# STM32L0x0 register map
File version: 1.1
CPU: CM0+ r0p0, little endian, MPU, no FPU, 4 interrupt priority bits
Registers are 32-bit, read-write, reset 0x0 unless marked. A register's access mark holds for its fields unless they carry their own. Offsets are from the block's base; [hi:lo] are bit positions; {n}, {i} and the like mark numbered series.

## Flash
Base 0x40022000
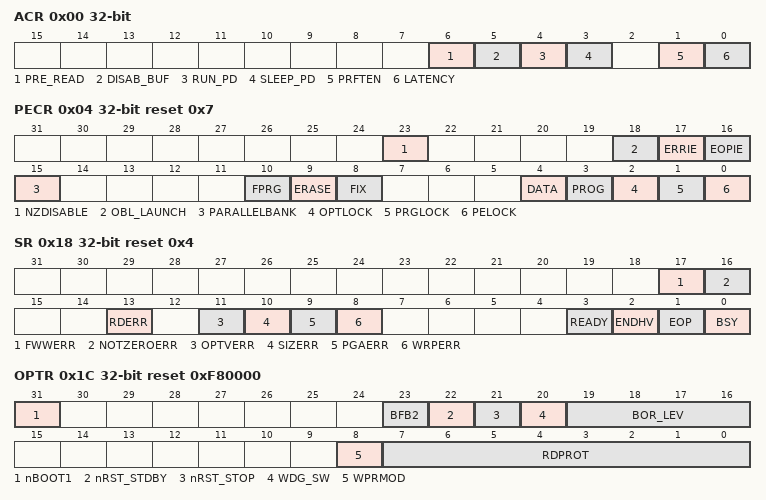
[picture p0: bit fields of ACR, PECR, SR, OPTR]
0x00 ACR — Access control register
  [6] PRE_READ — Pre-read data address
  [5] DISAB_BUF — Disable Buffer
  [4] RUN_PD — Flash mode during Run
  [3] SLEEP_PD — Flash mode during Sleep
  [1] PRFTEN — Prefetch enable
  [0] LATENCY
0x04 PECR reset 0x7 — Program/erase control register
  [23] NZDISABLE — Non-Zero check notification disable
  [18] OBL_LAUNCH — Launch the option byte loading
  [17] ERRIE — Error interrupt enable
  [16] EOPIE — End of programming interrupt enable
  [15] PARALLELBANK — Parallel bank mode
  [10] FPRG — Half Page/Double Word programming mode
  [9] ERASE — Page or Double Word erase mode
  [8] FIX — Fixed time data write for Byte, Half Word and Word programming
  [4] DATA — Data EEPROM selection
  [3] PROG — Program memory selection
  [2] OPTLOCK — Option bytes block lock
  [1] PRGLOCK — Program memory lock
  [0] PELOCK — FLASH_PECR and data EEPROM lock
0x08 PDKEYR wo — Power down key register
  [31:0] PDKEYR — RUN_PD in FLASH_ACR key
0x0C PEKEYR wo — Program/erase key register
  [31:0] PEKEYR — FLASH_PEC and data EEPROM key
0x10 PRGKEYR wo — Program memory key register
  [31:0] PRGKEYR — Program memory key
0x14 OPTKEYR wo — Option byte key register
  [31:0] OPTKEYR — Option byte key
0x18 SR access per field reset 0x4 — Status register
  [17] FWWERR rw
  [16] NOTZEROERR rw
  [13] RDERR rw
  [11] OPTVERR rw — Option validity error
  [10] SIZERR rw — Size error
  [9] PGAERR rw — Programming alignment error
  [8] WRPERR rw — Write protected error
  [3] READY ro — Flash memory module ready after low power mode
  [2] ENDHV ro — End of high voltage
  [1] EOP ro — End of operation
  [0] BSY ro — Write/erase operations in progress
0x1C OPTR ro reset 0xF80000 — Option byte register
  [31] nBOOT1
  [23] BFB2
  [22] nRST_STDBY
  [21] nRST_STOP
  [20] WDG_SW
  [19:16] BOR_LEV
  [8] WPRMOD
  [7:0] RDPROT — Read protection
0x20 WRPROT1 ro — Write protection register
  [31:0] WRPROT1 — Write protection
0x80 WRPROT2 ro — Write protection register
  [15:0] WRPROT2 — Write protection

## EXTI — External interrupt/event controller
Base 0x40010400
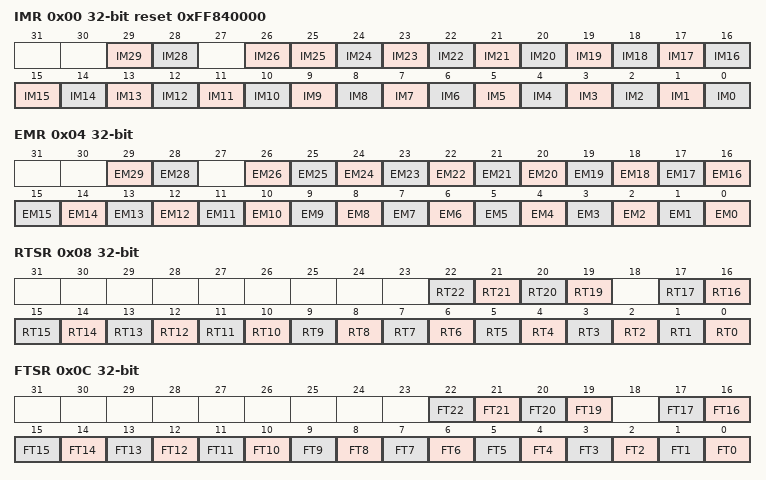
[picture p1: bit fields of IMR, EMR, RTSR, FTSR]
0x00 IMR reset 0xFF840000 — Interrupt mask register (EXTI_IMR)
  [29] IM29 — Interrupt Mask on line 27
  [28] IM28 — Interrupt Mask on line 27
  [26] IM26 — Interrupt Mask on line 27
  [n] IM{n} (n=0..25) — Interrupt Mask on line {n}
0x04 EMR — Event mask register (EXTI_EMR)
  [29] EM29 — Event Mask on line 29
  [28] EM28 — Event Mask on line 28
  [n] EM{n} (n=0..26) — Event Mask on line {n}
0x08 RTSR — Rising Trigger selection register (EXTI_RTSR)
  [n] RT{n} (n=19..22) — Rising trigger event configuration of line {n}
  [n] RT{n} (n=0..17) — Rising trigger event configuration of line {n}
0x0C FTSR — Falling Trigger selection register (EXTI_FTSR)
  [n] FT{n} (n=19..22) — Falling trigger event configuration of line {n}
  [n] FT{n} (n=0..17) — Falling trigger event configuration of line {n}
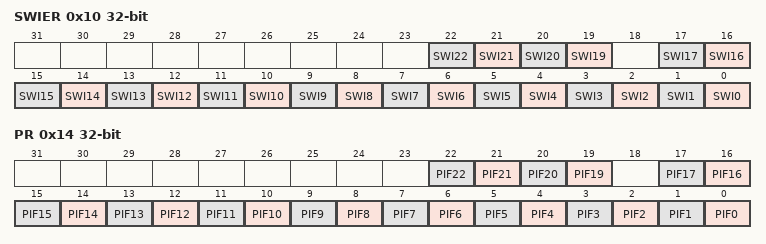
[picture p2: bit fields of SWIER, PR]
0x10 SWIER — Software interrupt event register (EXTI_SWIER)
  [n] SWI{n} (n=19..22) — Software Interrupt on line {n}
  [n] SWI{n} (n=0..17) — Software Interrupt on line {n}
0x14 PR — Pending register (EXTI_PR)
  [n] PIF{n} (n=19..22) — Pending bit {n}
  [n] PIF{n} (n=0..17) — Pending bit {n}

## ADC — Analog-to-digital converter
Base 0x40012400
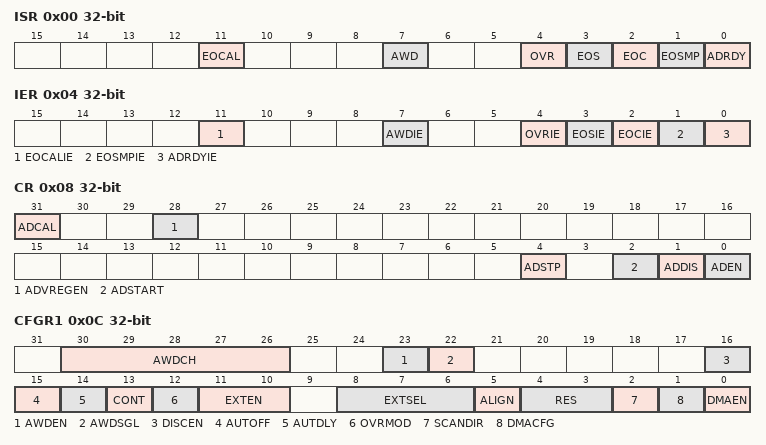
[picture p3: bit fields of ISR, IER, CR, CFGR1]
0x00 ISR — interrupt and status register
  [11] EOCAL — End Of Calibration flag
  [7] AWD — Analog watchdog flag
  [4] OVR — ADC overrun
  [3] EOS — End of sequence flag
  [2] EOC — End of conversion flag
  [1] EOSMP — End of sampling flag
  [0] ADRDY — ADC ready
0x04 IER — interrupt enable register
  [11] EOCALIE — End of calibration interrupt enable
  [7] AWDIE — Analog watchdog interrupt enable
  [4] OVRIE — Overrun interrupt enable
  [3] EOSIE — End of conversion sequence interrupt enable
  [2] EOCIE — End of conversion interrupt enable
  [1] EOSMPIE — End of sampling flag interrupt enable
  [0] ADRDYIE — ADC ready interrupt enable
0x08 CR — control register
  [31] ADCAL — ADC calibration
  [28] ADVREGEN — ADC Voltage Regulator Enable
  [4] ADSTP — ADC stop conversion command
  [2] ADSTART — ADC start conversion command
  [1] ADDIS — ADC disable command
  [0] ADEN — ADC enable command
0x0C CFGR1 — configuration register 1
  [30:26] AWDCH — Analog watchdog channel selection
  [23] AWDEN — Analog watchdog enable
  [22] AWDSGL — Enable the watchdog on a single channel or on all channels
  [16] DISCEN — Discontinuous mode
  [15] AUTOFF — Auto-off mode
  [14] AUTDLY — Auto-delayed conversion mode
  [13] CONT — Single / continuous conversion mode
  [12] OVRMOD — Overrun management mode
  [11:10] EXTEN — External trigger enable and polarity selection
  [8:6] EXTSEL — External trigger selection
  [5] ALIGN — Data alignment
  [4:3] RES — Data resolution
  [2] SCANDIR — Scan sequence direction
  [1] DMACFG — Direct memery access configuration
  [0] DMAEN — Direct memory access enable
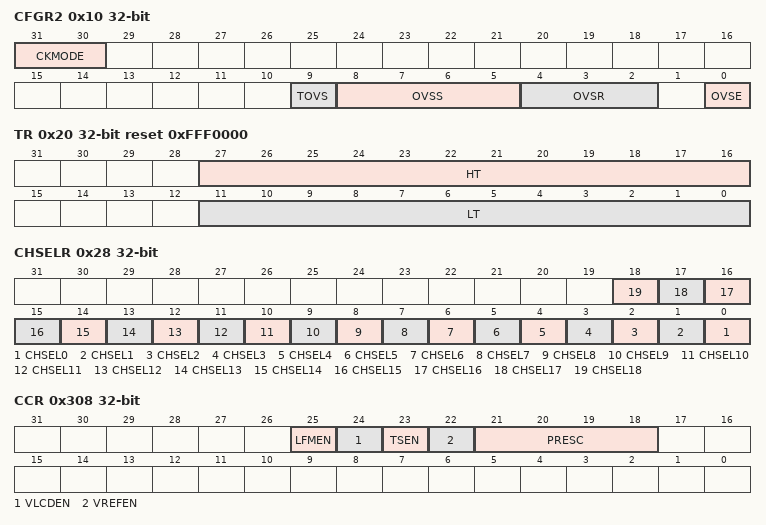
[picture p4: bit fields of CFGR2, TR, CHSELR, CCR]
0x10 CFGR2 — configuration register 2
  [31:30] CKMODE — ADC clock mode
  [9] TOVS — Triggered Oversampling
  [8:5] OVSS — Oversampling shift
  [4:2] OVSR — Oversampling ratio
  [0] OVSE — Oversampler Enable
0x14 SMPR — sampling time register
  [2:0] SMPR — Sampling time selection
0x20 TR reset 0xFFF0000 — watchdog threshold register
  [27:16] HT — Analog watchdog higher threshold
  [11:0] LT — Analog watchdog lower threshold
0x28 CHSELR — channel selection register
  [n] CHSEL{n} (n=0..18) — Channel-x selection
0x40 DR ro — data register
  [15:0] DATA — Converted data
0xB4 CALFACT — ADC Calibration factor
  [6:0] CALFACT — Calibration factor
0x308 CCR — ADC common configuration register
  [25] LFMEN — Low Frequency Mode enable
  [24] VLCDEN — VLCD enable
  [23] TSEN — Temperature sensor enable
  [22] VREFEN — VREFINT enable
  [21:18] PRESC — ADC prescaler
